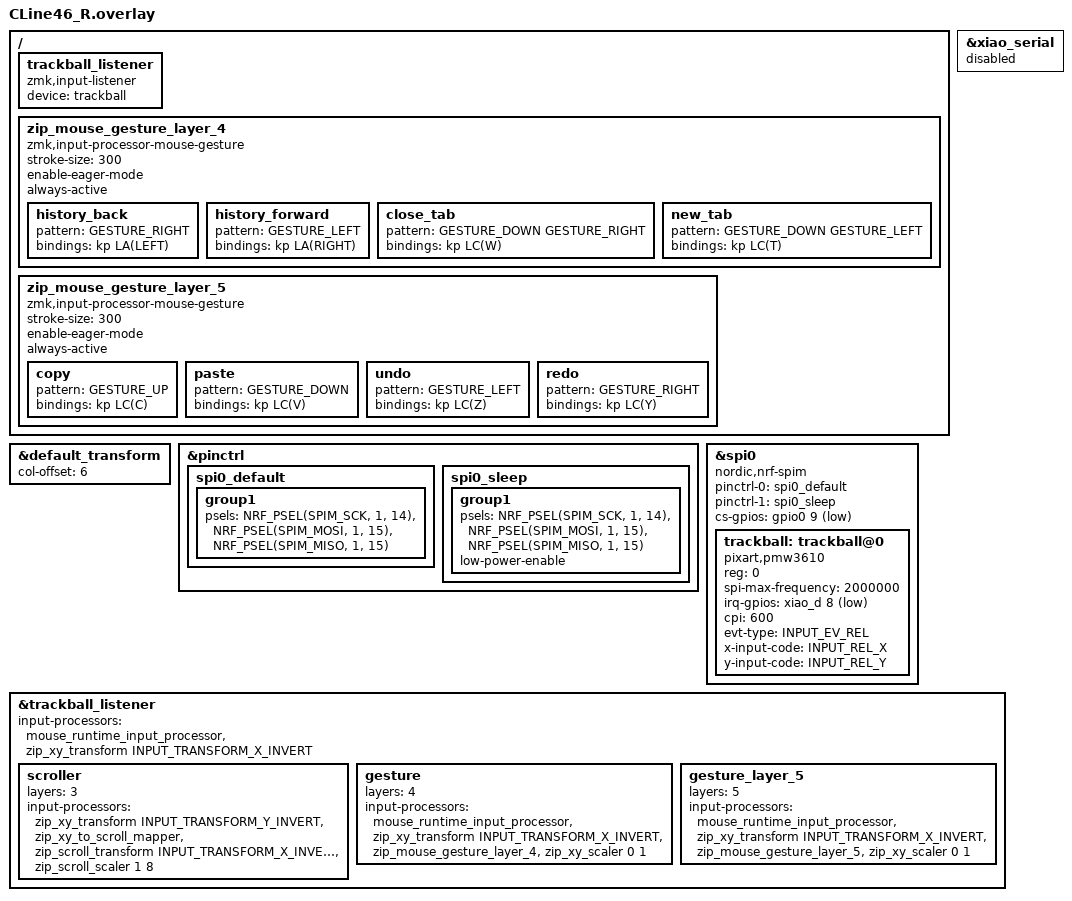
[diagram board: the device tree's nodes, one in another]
#include "CLine46.dtsi"
#include <zephyr/dt-bindings/input/input-event-codes.h>
#include <input/processors.dtsi>
#include <input/processors/runtime-input-processor.dtsi>
#include <behaviors/battery_history_request.dtsi>

&default_transform {
    col-offset = <6>;
};


/ {
    trackball_listener {
        status = "okay";
        compatible = "zmk,input-listener";
        device = <&trackball>;
    };
};

&pinctrl {
    spi0_default: spi0_default {
        group1 {
            psels = <NRF_PSEL(SPIM_SCK, 1, 14)>,
                <NRF_PSEL(SPIM_MOSI, 1, 15)>,
                <NRF_PSEL(SPIM_MISO, 1, 15)>;
        };
    };

    spi0_sleep: spi0_sleep {
        group1 {
            psels = <NRF_PSEL(SPIM_SCK, 1, 14)>,
                <NRF_PSEL(SPIM_MOSI, 1, 15)>,
                <NRF_PSEL(SPIM_MISO, 1, 15)>;
            low-power-enable;
        };
    };
};


&xiao_serial { status = "disabled"; };

&spi0 {
    status = "okay";
    compatible = "nordic,nrf-spim";
    pinctrl-0 = <&spi0_default>;
    pinctrl-1 = <&spi0_sleep>;
    pinctrl-names = "default", "sleep";
    cs-gpios = <&gpio0 9 GPIO_ACTIVE_LOW>;  //P0.09を指定(CS)

    trackball: trackball@0 {
        status = "okay";
        compatible = "pixart,pmw3610";
        reg = <0>;
        spi-max-frequency = <2000000>;
        irq-gpios = <&xiao_d 8 (GPIO_ACTIVE_LOW | GPIO_PULL_UP)>;
        cpi = <600>;
        //swap-xy;
        evt-type = <INPUT_EV_REL>;
        x-input-code = <INPUT_REL_X>;
        y-input-code = <INPUT_REL_Y>;
    };
};

// Overrides for the input listener node
&trackball_listener {
    status = "okay";
    input-processors =<&mouse_runtime_input_processor>,
        //<&zip_xy_transform INPUT_TRANSFORM_Y_INVERT>;         //Y軸反転
        //<&zip_xy_transform INPUT_TRANSFORM_XY_SWAP>,        //X軸とY軸の入れ替え
        <&zip_xy_transform INPUT_TRANSFORM_X_INVERT>;       //X軸反転
        //<&zip_temp_layer 2 1000>;                            //オートマウスレイヤーの選択;


    scroller {
        layers = <3>;
        input-processors = 
            // <&zip_xy_transform INPUT_TRANSFORM_XY_SWAP>,        //X軸とY軸の入れ替え
            // <&zip_xy_transform INPUT_TRANSFORM_X_INVERT>,       //X軸反転
            <&zip_xy_transform INPUT_TRANSFORM_Y_INVERT>,       //Y軸反転
            <&zip_xy_to_scroll_mapper>,                         //スクロールモードに変更
            <&zip_scroll_transform INPUT_TRANSFORM_X_INVERT>,   //スクロールのX軸反転
            //<&zip_scroll_transform INPUT_TRANSFORM_Y_INVERT>,   //スクロールのY軸反転
            <&zip_scroll_scaler 1 8>;                           //スクロール量を1/8倍
    };

    gesture {
        layers = <4>;
        input-processors = <&mouse_runtime_input_processor>,
            //<&zip_xy_transform INPUT_TRANSFORM_Y_INVERT>;         //Y軸反転
            //<&zip_xy_transform INPUT_TRANSFORM_XY_SWAP>,          //X軸とY軸の入れ替え
            <&zip_xy_transform INPUT_TRANSFORM_X_INVERT>,         //X軸反転
            <&zip_mouse_gesture_layer_4>,
            <&zip_xy_scaler 0 1>;                                 //ジェスチャー中はカーソルを動かさない
    };

    gesture_layer_5 {
        layers = <5>;
        input-processors = <&mouse_runtime_input_processor>,
            //<&zip_xy_transform INPUT_TRANSFORM_Y_INVERT>;         //Y軸反転
            //<&zip_xy_transform INPUT_TRANSFORM_XY_SWAP>,          //X軸とY軸の入れ替え
            <&zip_xy_transform INPUT_TRANSFORM_X_INVERT>,         //X軸反転
            <&zip_mouse_gesture_layer_5>,
            <&zip_xy_scaler 0 1>;                                 //ジェスチャー中はカーソルを動かさない
    };
};

/ {
    zip_mouse_gesture_layer_4: zip_mouse_gesture_layer_4 {
        compatible = "zmk,input-processor-mouse-gesture";
        #input-processor-cells = <0>;
        stroke-size = <300>;
        enable-eager-mode;
        always-active;

        history_back {
            pattern = <GESTURE_RIGHT>;
            bindings = <&kp LA(LEFT)>;
        };

        history_forward {
            pattern = <GESTURE_LEFT>;
            bindings = <&kp LA(RIGHT)>;
        };

        close_tab {
            pattern = <GESTURE_DOWN GESTURE_RIGHT>;
            bindings = <&kp LC(W)>;
        };

        new_tab {
            pattern = <GESTURE_DOWN GESTURE_LEFT>;
            bindings = <&kp LC(T)>;
        };
    };

    zip_mouse_gesture_layer_5: zip_mouse_gesture_layer_5 {
        compatible = "zmk,input-processor-mouse-gesture";
        #input-processor-cells = <0>;
        stroke-size = <300>;
        enable-eager-mode;
        always-active;

        copy {
            pattern = <GESTURE_UP>;
            bindings = <&kp LC(C)>;
        };

        paste {
            pattern = <GESTURE_DOWN>;
            bindings = <&kp LC(V)>;
        };

        undo {
            pattern = <GESTURE_LEFT>;
            bindings = <&kp LC(Z)>;
        };

        redo {
            pattern = <GESTURE_RIGHT>;
            bindings = <&kp LC(Y)>;
        };
    };
};
